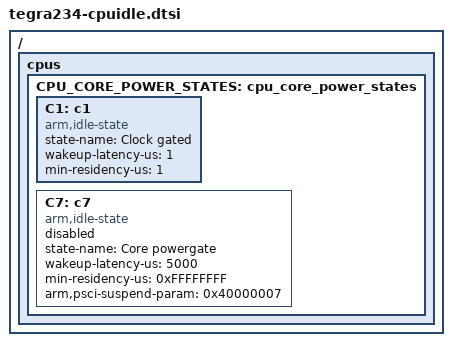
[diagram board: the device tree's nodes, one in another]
/*
 * Copyright (c) 2021, NVIDIA CORPORATION.  All rights reserved.
 *
 * This program is distributed in the hope it will be useful, but WITHOUT
 * ANY WARRANTY; without even the implied warranty of MERCHANTABILITY or
 * FITNESS FOR A PARTICULAR PURPOSE.  See the GNU General Public License for
 * more details.
 *
 * You should have received a copy of the GNU General Public License
 * along with this program.  If not, see <http://www.gnu.org/licenses/>.
 */

/ {
	cpus {
		CPU_CORE_POWER_STATES: cpu_core_power_states {

			C1: c1 {
				compatible = "arm,idle-state";
				state-name = "Clock gated";
				wakeup-latency-us = <1>;
				min-residency-us = <1>;
				status = "okay";
			};
			C7: c7 {
				compatible = "arm,idle-state";
				state-name = "Core powergate";
				wakeup-latency-us = <5000>;
				min-residency-us = <0xFFFFFFFF>;
				arm,psci-suspend-param= <0x40000007>;
				status = "disabled";
			};
		};

	};
};
